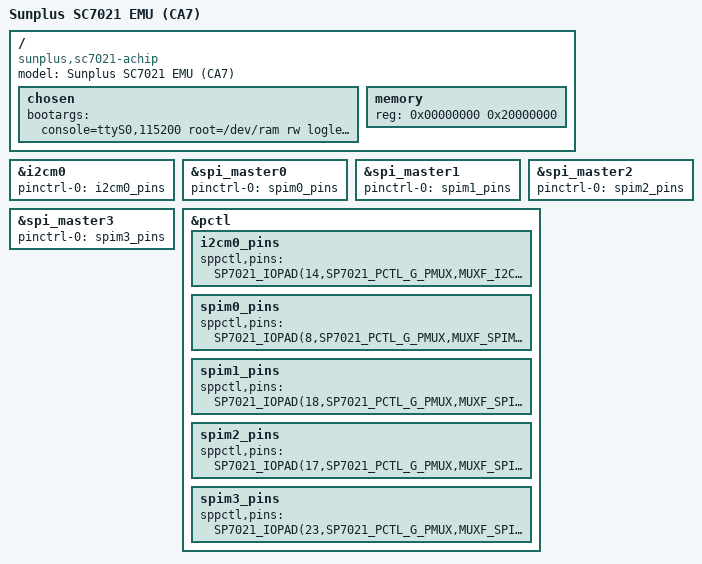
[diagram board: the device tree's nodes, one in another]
/dts-v1/;

#include "pentagram-sp7021-achip.dtsi"

#include <dt-bindings/interrupt-controller/arm-gic.h>

/ {
	model = "Sunplus SC7021 EMU (CA7)";
	compatible = "sunplus,sc7021-achip";

	chosen {
		bootargs = "console=ttyS0,115200 root=/dev/ram rw loglevel=8 user_debug=255 earlyprintk";
	};

	memory {
		reg = <0x00000000 0x20000000>; /* 512MB */
	};
};

&i2cm0{
 pinctrl-names = "default";
 pinctrl-0 = <&i2cm0_pins>;
};


&spi_master0 {
 pinctrl-names = "default";
 pinctrl-0 = <&spim0_pins>;
};

&spi_master1 {
 pinctrl-names = "default";
 pinctrl-0 = <&spim1_pins>;
};

&spi_master2 {
 pinctrl-names = "default";
 pinctrl-0 = <&spim2_pins>;
};


&spi_master3 {
 pinctrl-names = "default";
 pinctrl-0 = <&spim3_pins>;
};

&pctl {

 i2cm0_pins: i2cm0_pins {                                   
  sppctl,pins = <                                            
       SP7021_IOPAD(14,SP7021_PCTL_G_PMUX,MUXF_I2CM0_CK,0) 
       SP7021_IOPAD(15,SP7021_PCTL_G_PMUX,MUXF_I2CM0_DAT,0)        
  >;                                                        
 }; 
 
 /*** non-device binded ***/
 spim0_pins: spim0_pins {                                   
  sppctl,pins = <                                           
       SP7021_IOPAD(8,SP7021_PCTL_G_PMUX,MUXF_SPIM0_INT,0)  
       SP7021_IOPAD(9,SP7021_PCTL_G_PMUX,MUXF_SPIM0_CLK,0)  
       SP7021_IOPAD(10,SP7021_PCTL_G_PMUX,MUXF_SPIM0_EN,0)  
       SP7021_IOPAD(11,SP7021_PCTL_G_PMUX,MUXF_SPIM0_DO,0)  
       SP7021_IOPAD(12,SP7021_PCTL_G_PMUX,MUXF_SPIM0_DI,0)  
  >;                                                        
 };                                                         
 spim1_pins: spim1_pins {                                   
  sppctl,pins = <                                           
       SP7021_IOPAD(18,SP7021_PCTL_G_PMUX,MUXF_SPIM1_INT,0) 
       SP7021_IOPAD(19,SP7021_PCTL_G_PMUX,MUXF_SPIM1_CLK,0) 
       SP7021_IOPAD(20,SP7021_PCTL_G_PMUX,MUXF_SPIM1_EN,0)  
       SP7021_IOPAD(21,SP7021_PCTL_G_PMUX,MUXF_SPIM1_DO,0)  
       SP7021_IOPAD(22,SP7021_PCTL_G_PMUX,MUXF_SPIM1_DI,0)  
  >;                                                        
 };                                                         
 spim2_pins: spim2_pins {                                   
  sppctl,pins = <                                           
       //SP7021_IOPAD(13,SP7021_PCTL_G_PMUX,MUXF_SPIM2_INT,0) 
       //SP7021_IOPAD(14,SP7021_PCTL_G_PMUX,MUXF_SPIM2_CLK,0) 
       //SP7021_IOPAD(15,SP7021_PCTL_G_PMUX,MUXF_SPIM2_EN,0)  
       //SP7021_IOPAD(16,SP7021_PCTL_G_PMUX,MUXF_SPIM2_DO,0)  
       SP7021_IOPAD(17,SP7021_PCTL_G_PMUX,MUXF_SPIM2_DI,0)  
  >;                                                        
 };                                                         
 spim3_pins: spim3_pins {                                   
  sppctl,pins = <                                           
       SP7021_IOPAD(23,SP7021_PCTL_G_PMUX,MUXF_SPIM3_INT,0)  
       SP7021_IOPAD(24,SP7021_PCTL_G_PMUX,MUXF_SPIM3_CLK,0)  
       SP7021_IOPAD(25,SP7021_PCTL_G_PMUX,MUXF_SPIM3_EN,0)   
       SP7021_IOPAD(26,SP7021_PCTL_G_PMUX,MUXF_SPIM3_DO,0)   
       SP7021_IOPAD(27,SP7021_PCTL_G_PMUX,MUXF_SPIM3_DI,0)   
                                                            
       SP7021_IOPAD(35,SP7021_PCTL_G_PMUX,MUXF_SPI3S_INT,0) 
       SP7021_IOPAD(36,SP7021_PCTL_G_PMUX,MUXF_SPI3S_CLK,0) 
       SP7021_IOPAD(37,SP7021_PCTL_G_PMUX,MUXF_SPI3S_EN,0)  
       SP7021_IOPAD(38,SP7021_PCTL_G_PMUX,MUXF_SPI3S_DO,0)  
       SP7021_IOPAD(39,SP7021_PCTL_G_PMUX,MUXF_SPI3S_DI,0)  
                                                            
  >;                                                        
 };      
 };



